VERSION "1.0"

NS_ :

BS_:

BU_: BMS EST

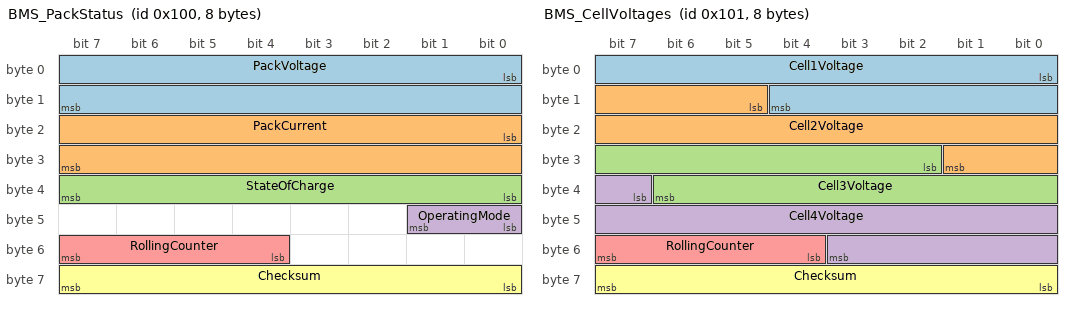
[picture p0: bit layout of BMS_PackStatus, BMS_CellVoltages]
BO_ 256 BMS_PackStatus: 8 BMS
 SG_ PackVoltage : 0|16@1+ (0.01,0) [0|655.35] "V" EST
 SG_ PackCurrent : 16|16@1- (0.01,0) [-327.68|327.67] "A" EST
 SG_ StateOfCharge : 32|8@1+ (0.5,0) [0|100] "%" EST
 SG_ OperatingMode : 40|2@1+ (1,0) [0|3] "" EST
 SG_ RollingCounter : 52|4@1+ (1,0) [0|15] "" EST
 SG_ Checksum : 56|8@1+ (1,0) [0|255] "" EST

BO_ 257 BMS_CellVoltages: 8 BMS
 SG_ Cell1Voltage : 0|13@1+ (0.001,0) [0|8.191] "V" EST
 SG_ Cell2Voltage : 13|13@1+ (0.001,0) [0|8.191] "V" EST
 SG_ Cell3Voltage : 26|13@1+ (0.001,0) [0|8.191] "V" EST
 SG_ Cell4Voltage : 39|13@1+ (0.001,0) [0|8.191] "V" EST
 SG_ RollingCounter : 52|4@1+ (1,0) [0|15] "" EST
 SG_ Checksum : 56|8@1+ (1,0) [0|255] "" EST

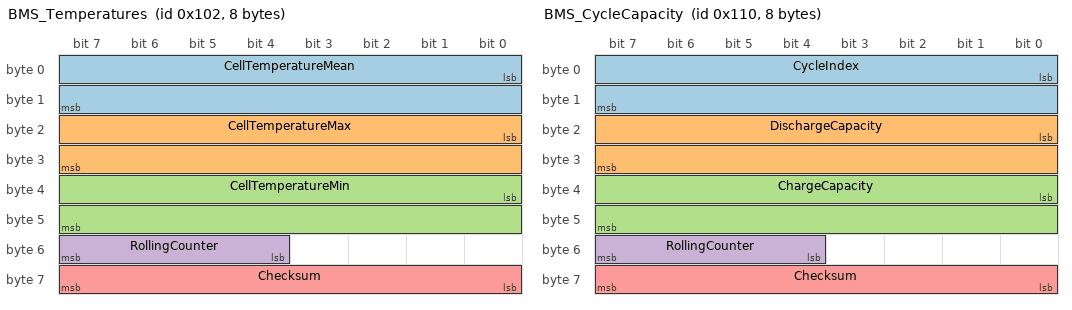
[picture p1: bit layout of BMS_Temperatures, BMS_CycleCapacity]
BO_ 258 BMS_Temperatures: 8 BMS
 SG_ CellTemperatureMean : 0|16@1- (0.01,0) [-40|125] "degC" EST
 SG_ CellTemperatureMax : 16|16@1- (0.01,0) [-40|125] "degC" EST
 SG_ CellTemperatureMin : 32|16@1- (0.01,0) [-40|125] "degC" EST
 SG_ RollingCounter : 52|4@1+ (1,0) [0|15] "" EST
 SG_ Checksum : 56|8@1+ (1,0) [0|255] "" EST

BO_ 272 BMS_CycleCapacity: 8 BMS
 SG_ CycleIndex : 0|16@1+ (1,0) [0|65535] "" EST
 SG_ DischargeCapacity : 16|16@1+ (0.0001,0) [0|6.5535] "Ah" EST
 SG_ ChargeCapacity : 32|16@1+ (0.0001,0) [0|6.5535] "Ah" EST
 SG_ RollingCounter : 52|4@1+ (1,0) [0|15] "" EST
 SG_ Checksum : 56|8@1+ (1,0) [0|255] "" EST

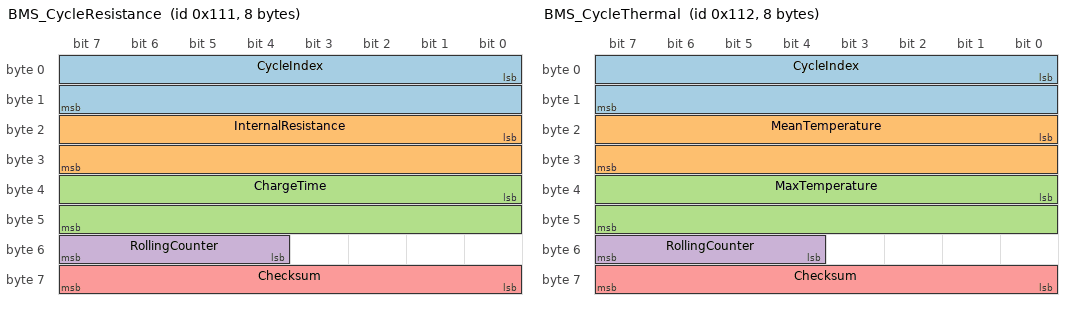
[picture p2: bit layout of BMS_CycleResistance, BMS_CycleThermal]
BO_ 273 BMS_CycleResistance: 8 BMS
 SG_ CycleIndex : 0|16@1+ (1,0) [0|65535] "" EST
 SG_ InternalResistance : 16|16@1+ (1E-05,0) [0|0.65535] "Ohm" EST
 SG_ ChargeTime : 32|16@1+ (0.01,0) [0|655.35] "min" EST
 SG_ RollingCounter : 52|4@1+ (1,0) [0|15] "" EST
 SG_ Checksum : 56|8@1+ (1,0) [0|255] "" EST

BO_ 274 BMS_CycleThermal: 8 BMS
 SG_ CycleIndex : 0|16@1+ (1,0) [0|65535] "" EST
 SG_ MeanTemperature : 16|16@1- (0.01,0) [-40|125] "degC" EST
 SG_ MaxTemperature : 32|16@1- (0.01,0) [-40|125] "degC" EST
 SG_ RollingCounter : 52|4@1+ (1,0) [0|15] "" EST
 SG_ Checksum : 56|8@1+ (1,0) [0|255] "" EST

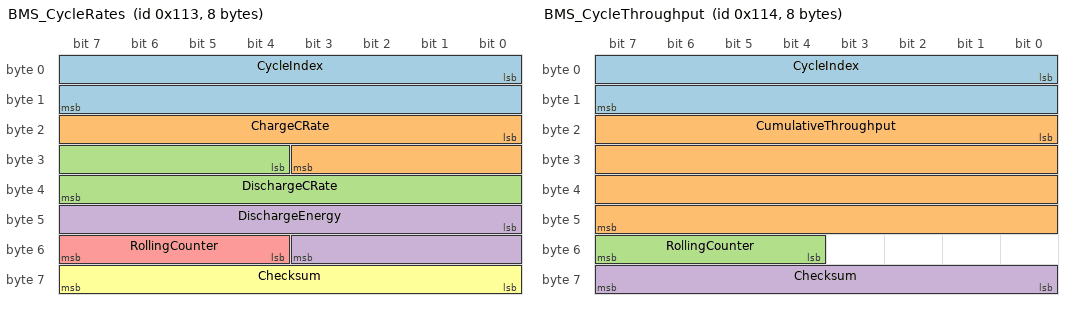
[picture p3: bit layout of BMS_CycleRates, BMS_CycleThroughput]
BO_ 275 BMS_CycleRates: 8 BMS
 SG_ CycleIndex : 0|16@1+ (1,0) [0|65535] "" EST
 SG_ ChargeCRate : 16|12@1+ (0.002,0) [0|8.19] "C" EST
 SG_ DischargeCRate : 28|12@1+ (0.002,0) [0|8.19] "C" EST
 SG_ DischargeEnergy : 40|12@1+ (0.01,0) [0|40.95] "Wh" EST
 SG_ RollingCounter : 52|4@1+ (1,0) [0|15] "" EST
 SG_ Checksum : 56|8@1+ (1,0) [0|255] "" EST

BO_ 276 BMS_CycleThroughput: 8 BMS
 SG_ CycleIndex : 0|16@1+ (1,0) [0|65535] "" EST
 SG_ CumulativeThroughput : 16|32@1+ (0.001,0) [0|4294967.295] "Ah" EST
 SG_ RollingCounter : 52|4@1+ (1,0) [0|15] "" EST
 SG_ Checksum : 56|8@1+ (1,0) [0|255] "" EST

CM_ BU_ BMS "Battery management system of a 4S1P module. In this repository it is always the simulated node in cobalt.hal.can_node.";
CM_ BU_ EST "State-of-health and remaining-life estimator, cobalt.hal.can_bms.CanBms.";
CM_ BO_ 256 "Live pack status, sent several times per charge and discharge phase.";
CM_ BO_ 257 "Live terminal voltage of each series cell.";
CM_ BO_ 258 "Live cell temperature spread across the module.";
CM_ BO_ 272 "Cycle summary 1 of 5, sent once at the end of each full cycle. Capacities are per series cell.";
CM_ BO_ 273 "Cycle summary 2 of 5. Resistance is the per-cell DC estimate.";
CM_ BO_ 274 "Cycle summary 3 of 5.";
CM_ BO_ 275 "Cycle summary 4 of 5. Energy is per series cell.";
CM_ BO_ 276 "Cycle summary 5 of 5.";
CM_ SG_ 256 PackCurrent "Positive into the pack, so charging is positive and discharging negative.";
CM_ SG_ 256 RollingCounter "Increments by one per frame of this ID, modulo 16. A gap is a lost frame.";
CM_ SG_ 256 Checksum "Ones complement of the byte sum of data bytes 0 to 6 plus both bytes of the arbitration ID.";
CM_ SG_ 272 CycleIndex "Full equivalent cycle count modulo 65536. Joins the five summary frames of one cycle.";
CM_ SG_ 276 CumulativeThroughput "Discharged charge since commissioning, per series cell.";
VAL_ 256 OperatingMode 0 "Idle" 1 "Charge" 2 "Discharge" 3 "Fault" ;
